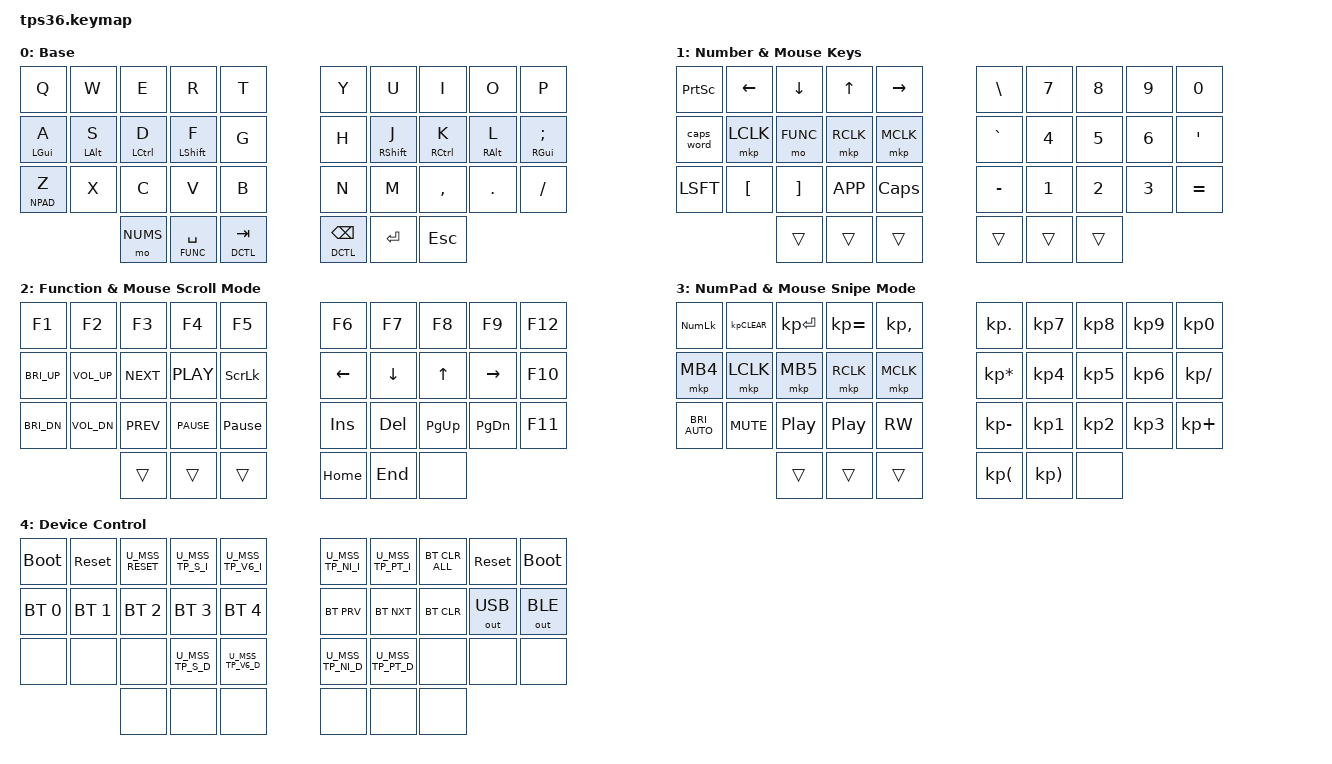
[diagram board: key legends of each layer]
#include <behaviors.dtsi>
#include <dt-bindings/zmk/bt.h>
#include <dt-bindings/zmk/keys.h>
#include <dt-bindings/zmk/outputs.h>
#include <dt-bindings/zmk/mouse.h>
// #include <behaviors/mouse_keys.dtsi>

// Enable mouse and trackpoint features
#define HAS_MOUSE_KEYS
#define HAS_MOUSE_TP

#include "include/mouse_tp.dtsi"

#define DFLT 0
#define NUMS 1
#define FUNC 2
#define NPAD 3
#define DCTL 4

&mt {
   flavor = "tap-preferred";
   tapping_term_ms = <200>;
   quick-tap-ms= <200>;
};

&lt {
   flavor = "tap-preferred";
   tapping_term_ms = <200>;
   quick-tap-ms= <200>;
};

/ {
    keymap {
        compatible = "zmk,keymap";
         
        default_layer {
            display-name = "Base";
            bindings = <
                &kp Q            &kp W            &kp E            &kp R            &kp T              &kp Y            &kp U            &kp I            &kp O            &kp P
                &mt LGUI A       &mt LALT S       &mt LCTRL D      &mt LSHFT F      &kp G              &kp H            &mt RSHFT J      &mt RCTRL K      &mt RALT L       &mt RGUI SEMI
                &lt NPAD Z       &kp X            &kp C            &kp V            &kp B              &kp N            &kp M            &kp COMMA        &kp DOT          &kp FSLH
                                                  &mo NUMS         &lt FUNC SPACE   &lt DCTL TAB       &lt DCTL BKSP    &kp ENTER        &kp ESC
            >;
        };

        number_mouse_layer {
            display-name = "Number & Mouse Keys";
            bindings = <
                &kp PSCRN        &kp LEFT         &kp DOWN         &kp UP           &kp RIGHT          &kp BSLH         &kp N7           &kp N8           &kp N9           &kp N0
                &caps_word       &mkp LCLK        &mo FUNC         &mkp RCLK        &mkp MCLK          &kp GRAVE        &kp N4           &kp N5           &kp N6           &kp APOS
                &kp LSFT         &kp LBKT         &kp RBKT         &kp K_APP        &kp CAPS           &kp MINUS        &kp N1           &kp N2           &kp N3           &kp EQUAL
                                                  &trans           &trans           &trans             &trans           &trans           &trans
            >;
        };
         
        function_scroll_layer {
            display-name = "Function & Mouse Scroll Mode";
            bindings = <
                &kp F1           &kp F2           &kp F3           &kp F4           &kp F5             &kp F6           &kp F7           &kp F8           &kp F9           &kp F12
                &kp C_BRI_UP     &kp C_VOL_UP     &kp C_NEXT       &kp C_PLAY       &kp SLCK           &kp LEFT         &kp DOWN         &kp UP           &kp RIGHT        &kp F10
                &kp C_BRI_DN     &kp C_VOL_DN     &kp C_PREV       &kp C_PAUSE      &kp PAUSE_BREAK    &kp INS          &kp DEL          &kp PG_UP        &kp PG_DN        &kp F11
                                                  &trans           &trans           &trans             &kp HOME         &kp END          &none
            >;
        };

        numpad_snipe_layer {
            display-name = "NumPad & Mouse Snipe Mode";
            bindings = <
                &kp KP_NLCK      &kp KP_CLEAR     &kp KP_ENTER     &kp KP_EQUAL     &kp KP_COMMA       &kp KP_DOT       &kp KP_N7        &kp KP_N8        &kp KP_N9        &kp KP_N0
                &mkp MB4         &mkp LCLK        &mkp MB5         &mkp RCLK        &mkp MCLK          &kp KP_MULTIPLY  &kp KP_N4        &kp KP_N5        &kp KP_N6        &kp KP_DIVIDE
                &kp C_BRI_AUTO   &kp C_MUTE       &kp C_PP         &kp C_PLAY_PAUSE &kp C_RW           &kp KP_MINUS     &kp KP_N1        &kp KP_N2        &kp KP_N3        &kp KP_PLUS
                                                  &trans           &trans           &trans             &kp KP_LPAR      &kp KP_RPAR      &none
            >;
        };
         
        device_control_layer {
            display-name = "Device Control";
            bindings = <
                &bootloader      &sys_reset       U_MSS_RESET      U_MSS_TP_S_I     U_MSS_TP_V6_I      U_MSS_TP_NI_I    U_MSS_TP_PT_I    &bt BT_CLR_ALL   &sys_reset       &bootloader
                &bt BT_SEL 0     &bt BT_SEL 1     &bt BT_SEL 2     &bt BT_SEL 3     &bt BT_SEL 4       &bt BT_PRV       &bt BT_NXT       &bt BT_CLR       &out OUT_USB     &out OUT_BLE
                &none            &none            &none            U_MSS_TP_S_D     U_MSS_TP_V6_D      U_MSS_TP_NI_D    U_MSS_TP_PT_D    &none            &none            &none 
                                                  &none            &none            &none              &none            &none            &none
            >;
        };
   	};
};
